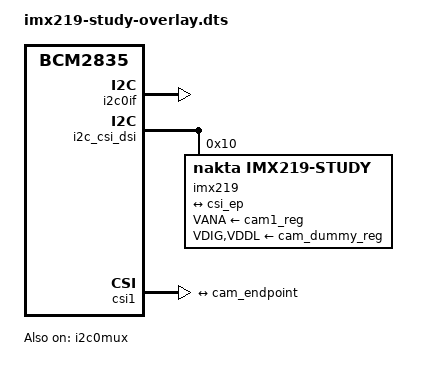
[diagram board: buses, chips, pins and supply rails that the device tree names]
// SPDX-License-Identifier: GPL-2.0-only
/dts-v1/;
/plugin/;

/ {
	compatible = "brcm,bcm2835";

	fragment@0 {
		target = <&i2c0if>;
		__overlay__ {
			status = "okay";
		};
	};

	fragment@1 {
		target = <&cam1_clk>;
		__overlay__ {
			status = "okay";
			clock-frequency = <24000000>;
		};
	};

	fragment@2 {
		target = <&i2c0mux>;
		__overlay__ {
			status = "okay";
		};
	};

	fragment@100 {
		target = <&i2c_csi_dsi>;
		__overlay__ {
			#address-cells = <1>;
			#size-cells = <0>;
			status = "okay";

			imx219@10 {
				compatible = "nakta,imx219-study";
				reg = <0x10>;
				status = "okay";

				clocks = <&cam1_clk>;
				clock-names = "xclk";
				VANA-supply = <&cam1_reg>;
				VDIG-supply = <&cam_dummy_reg>;
				VDDL-supply = <&cam_dummy_reg>;
				rotation = <180>;
				orientation = <2>;

				port {
					cam_endpoint: endpoint {
						remote-endpoint = <&csi_ep>;
						clock-lanes = <0>;
						data-lanes = <1 2>;
						clock-noncontinuous;
						link-frequencies = /bits/ 64 <456000000>;
					};
				};
			};
		};
	};

	fragment@101 {
		target = <&csi1>;
		__overlay__ {
			status = "okay";
			brcm,media-controller;

			port {
				csi_ep: endpoint {
					remote-endpoint = <&cam_endpoint>;
					clock-lanes = <0>;
					data-lanes = <1 2>;
					clock-noncontinuous;
				};
			};
		};
	};
};
